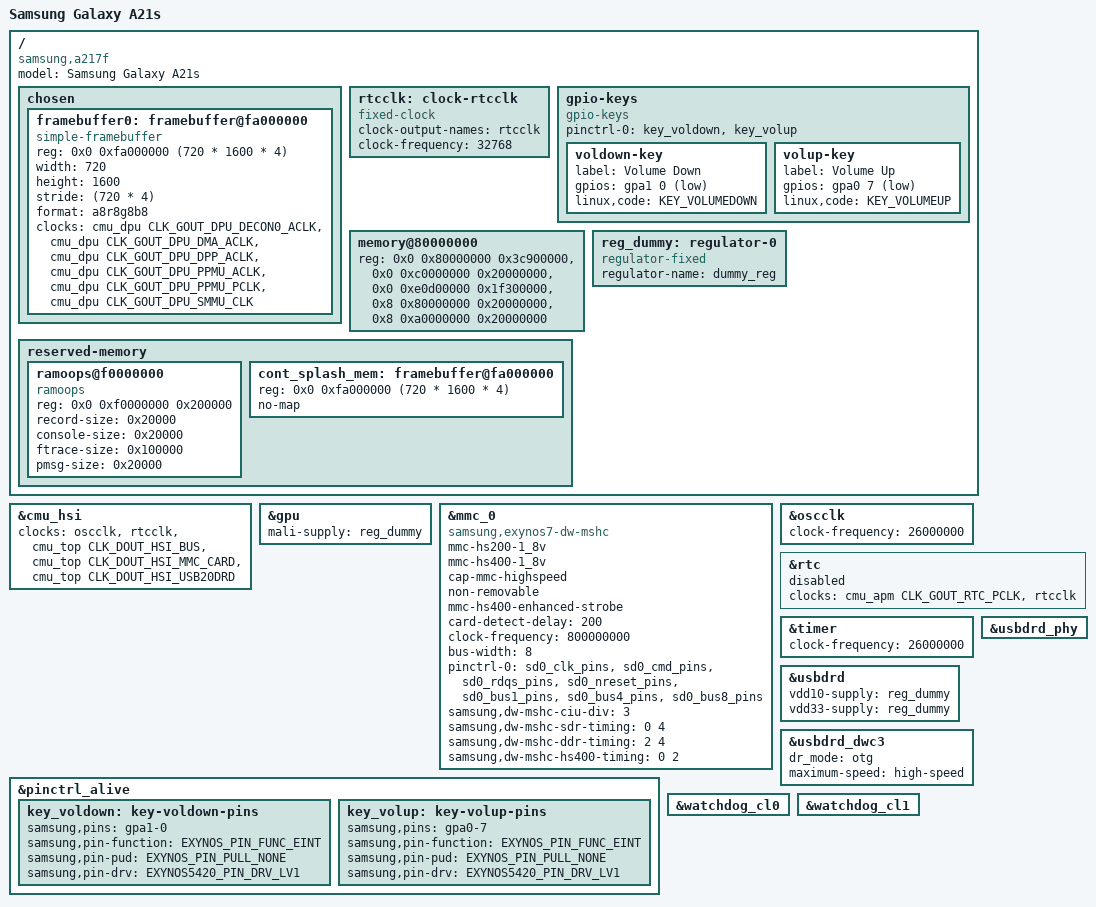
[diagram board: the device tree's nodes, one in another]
// SPDX-License-Identifier: GPL-2.0
/*
 * Samsung Galaxy A21s (a21s/SM-A217F) device tree source
 *
 * Copyright (c) 2026, Thomas Turner <tturner@lineageos.org>
 */

/dts-v1/;
#include "exynos850.dtsi"
#include <dt-bindings/gpio/gpio.h>
#include <dt-bindings/input/input.h>

/ {
	model = "Samsung Galaxy A21s";
	compatible = "samsung,a217f", "samsung,exynos850";

	chosen {
		ranges;
		#address-cells = <2>;
		#size-cells = <1>;

		framebuffer0: framebuffer@fa000000 {
			compatible = "simple-framebuffer";
			reg = <0x0 0xfa000000 (720 * 1600 * 4)>;
			width = <720>;
			height = <1600>;
			stride = <(720 * 4)>;
			format = "a8r8g8b8";
			clocks = <&cmu_dpu CLK_GOUT_DPU_DECON0_ACLK>,
				 <&cmu_dpu CLK_GOUT_DPU_DMA_ACLK>,
				 <&cmu_dpu CLK_GOUT_DPU_DPP_ACLK>,
				 <&cmu_dpu CLK_GOUT_DPU_PPMU_ACLK>,
				 <&cmu_dpu CLK_GOUT_DPU_PPMU_PCLK>,
				 <&cmu_dpu CLK_GOUT_DPU_SMMU_CLK>;
		};
	};

	/*
	 * RTC clock (XrtcXTI); external, must be 32.768 kHz.
	 *
	 * TODO: Remove this once RTC clock is implemented properly as part of
	 *       PMIC driver.
	 */
	rtcclk: clock-rtcclk {
		compatible = "fixed-clock";
		clock-output-names = "rtcclk";
		#clock-cells = <0>;
		clock-frequency = <32768>;
	};

	gpio-keys {
		compatible = "gpio-keys";
		pinctrl-0 = <&key_voldown &key_volup>;
		pinctrl-names = "default";

		voldown-key {
			label = "Volume Down";
			gpios = <&gpa1 0 GPIO_ACTIVE_LOW>;
			linux,code = <KEY_VOLUMEDOWN>;
		};

		volup-key {
			label = "Volume Up";
			gpios = <&gpa0 7 GPIO_ACTIVE_LOW>;
			linux,code = <KEY_VOLUMEUP>;
		};
	};

	memory@80000000 {
		device_type = "memory";
		reg = <0x0 0x80000000 0x3c900000>,
		      <0x0 0xc0000000 0x20000000>,
		      <0x0 0xe0d00000 0x1f300000>,
		      <0x8 0x80000000 0x20000000>,
		      <0x8 0xa0000000 0x20000000>;
	};

	/* TODO: Remove this once PMIC is implemented  */
	reg_dummy: regulator-0 {
		compatible = "regulator-fixed";
		regulator-name = "dummy_reg";
	};

	reserved-memory {
		ranges;
		#address-cells = <2>;
		#size-cells = <1>;

		ramoops@f0000000 {
			compatible = "ramoops";
			reg = <0x0 0xf0000000 0x200000>;
			record-size = <0x20000>;
			console-size = <0x20000>;
			ftrace-size = <0x100000>;
			pmsg-size = <0x20000>;
		};

		cont_splash_mem: framebuffer@fa000000 {
			reg = <0x0 0xfa000000 (720 * 1600 * 4)>;
			no-map;
		};
	};
};

&cmu_hsi {
	clocks = <&oscclk>, <&rtcclk>,
		 <&cmu_top CLK_DOUT_HSI_BUS>,
		 <&cmu_top CLK_DOUT_HSI_MMC_CARD>,
		 <&cmu_top CLK_DOUT_HSI_USB20DRD>;
	clock-names = "oscclk", "rtcclk", "dout_hsi_bus",
		      "dout_hsi_mmc_card", "dout_hsi_usb20drd";
};

&gpu {
	mali-supply = <&reg_dummy>;

	status = "okay";
};

&mmc_0 {
	compatible = "samsung,exynos7-dw-mshc";
	mmc-hs200-1_8v;
	mmc-hs400-1_8v;
	cap-mmc-highspeed;
	non-removable;
	mmc-hs400-enhanced-strobe;
	card-detect-delay = <200>;
	clock-frequency = <800000000>;
	bus-width = <8>;

	pinctrl-0 = <&sd0_clk_pins &sd0_cmd_pins &sd0_rdqs_pins &sd0_nreset_pins
		     &sd0_bus1_pins &sd0_bus4_pins &sd0_bus8_pins>;
	pinctrl-names = "default";

	samsung,dw-mshc-ciu-div = <3>;
	samsung,dw-mshc-sdr-timing = <0 4>;
	samsung,dw-mshc-ddr-timing = <2 4>;
	samsung,dw-mshc-hs400-timing = <0 2>;

	status = "okay";
};

&oscclk {
	clock-frequency = <26000000>;
};

&pinctrl_alive {
	key_voldown: key-voldown-pins {
		samsung,pins = "gpa1-0";
		samsung,pin-function = <EXYNOS_PIN_FUNC_EINT>;
		samsung,pin-pud = <EXYNOS_PIN_PULL_NONE>;
		samsung,pin-drv = <EXYNOS5420_PIN_DRV_LV1>;
	};

	key_volup: key-volup-pins {
		samsung,pins = "gpa0-7";
		samsung,pin-function = <EXYNOS_PIN_FUNC_EINT>;
		samsung,pin-pud = <EXYNOS_PIN_PULL_NONE>;
		samsung,pin-drv = <EXYNOS5420_PIN_DRV_LV1>;
	};
};

&rtc {
	clocks = <&cmu_apm CLK_GOUT_RTC_PCLK>, <&rtcclk>;
	clock-names = "rtc", "rtc_src";

	status = "disabled";
};

&timer {
	/*
	 * Non-updatable, broken stock Samsung bootloader does not
	 * configure CNTFRQ_EL0
	 */
	clock-frequency = <26000000>;
};

&usbdrd {
	vdd10-supply = <&reg_dummy>;
	vdd33-supply = <&reg_dummy>;

	status = "okay";
};

&usbdrd_dwc3 {
	dr_mode = "otg";
	maximum-speed = "high-speed";
};

&usbdrd_phy {
	status = "okay";
};

&watchdog_cl0 {
	status = "okay";
};

&watchdog_cl1 {
	status = "okay";
};
